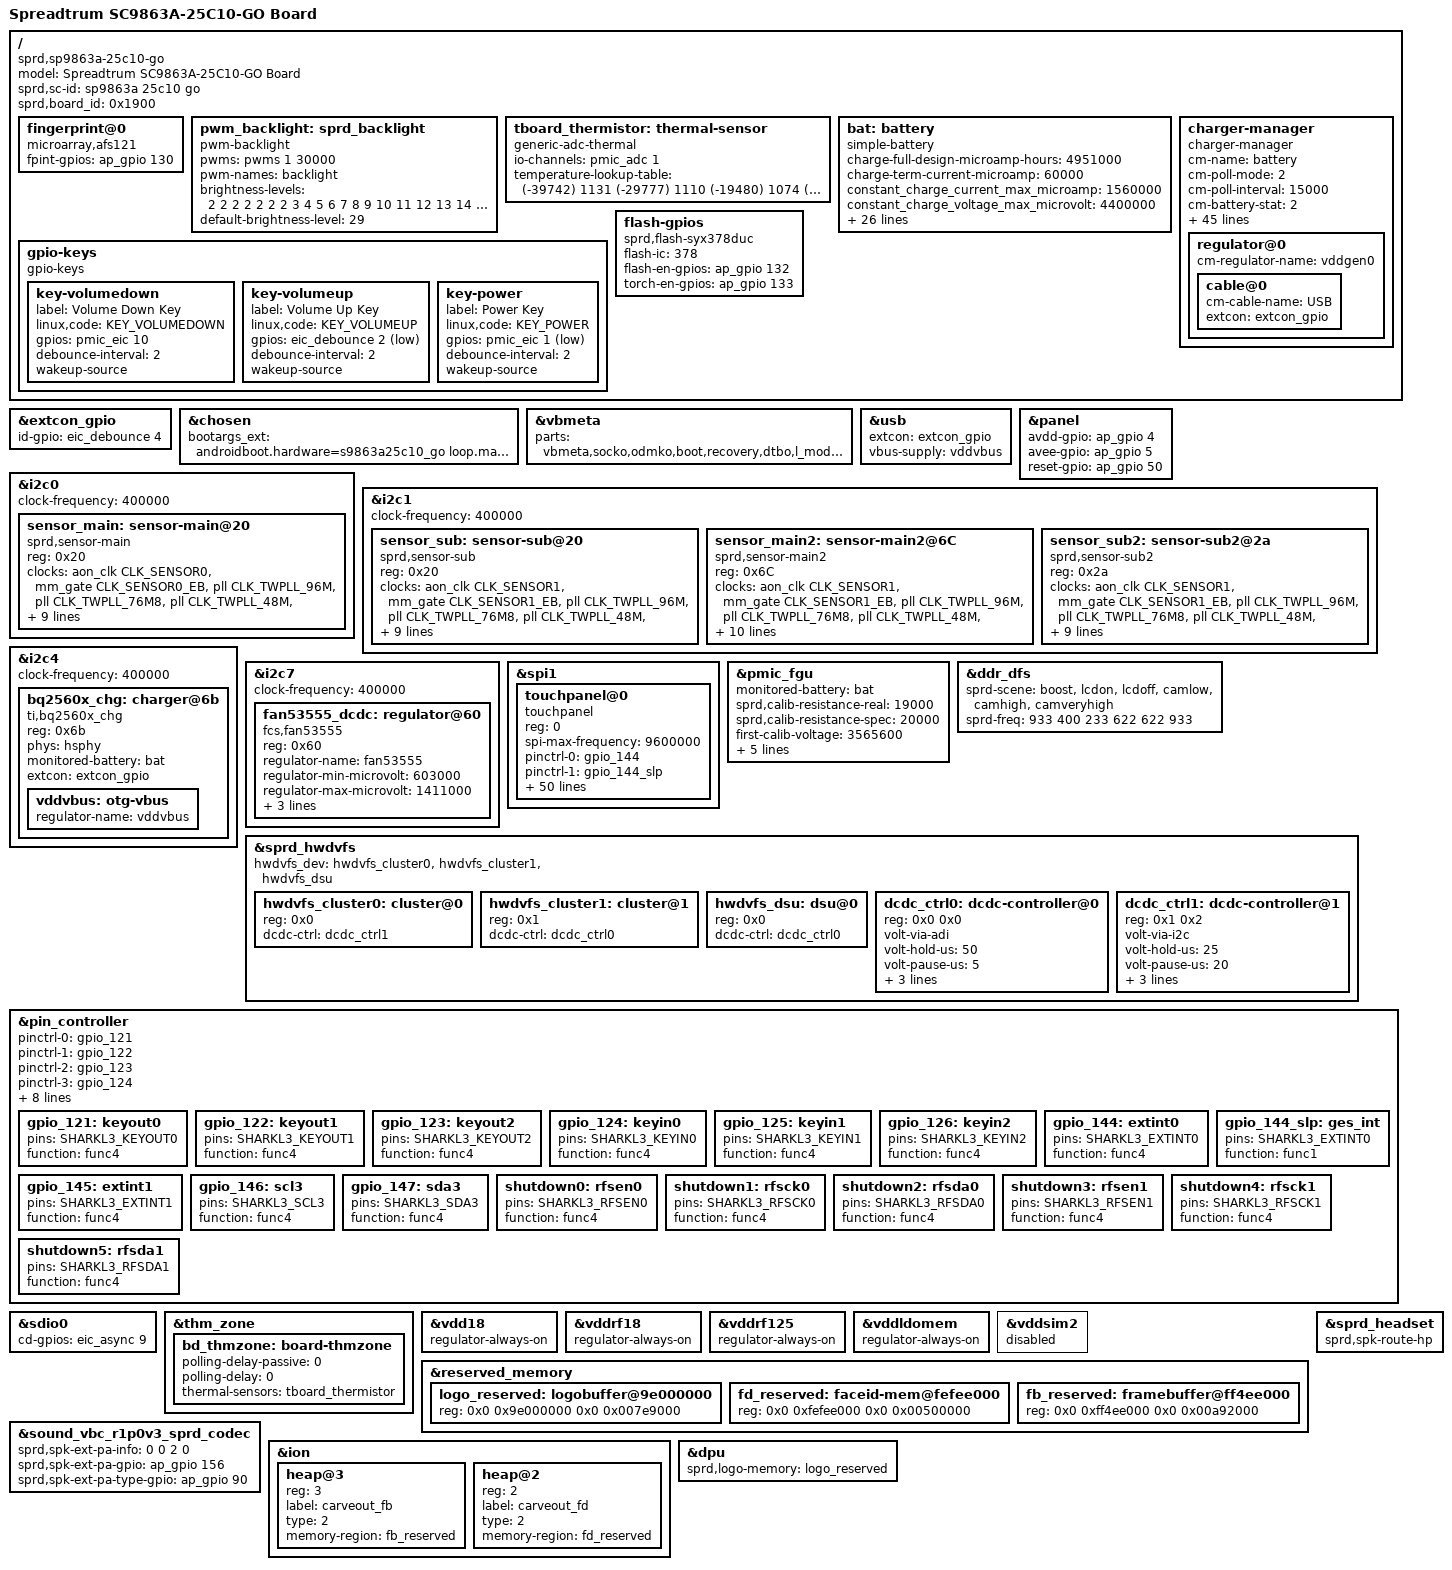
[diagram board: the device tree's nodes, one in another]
/dts-v1/;
/plugin/;

#include <dt-bindings/input/input.h>
#include <dt-bindings/gpio/gpio.h>
#include <dt-bindings/clock/sprd,sc9863a-clk.h>
#include "lcd/lcd_icnl9911c_truly_mipi_hdp.dtsi"
#include "lcd/lcd_nt35695_truly_mipi_fhd.dtsi"
#include "lcd/lcd_nt35532_truly_mipi_fhd.dtsi"
#include "lcd/lcd_nt35596_boe_mipi_fhd.dtsi"
#include "lcd/lcd_dummy_mipi.dtsi"

/ {
	model = "Spreadtrum SC9863A-25C10-GO Board";
	compatible = "sprd,sp9863a-25c10-go", "sprd,sc9863a";
	sprd,sc-id = "sp9863a 25c10 go";
	sprd,board_id = <0x1900>; //XX00:base board,XX00~XXFF:customize board

	fragment {
		target-path = "/";
		__overlay__ {
			fingerprint@0 {
				compatible = "microarray,afs121";
				fpint-gpios = <&ap_gpio 130 0>;
			};
			pwm_backlight: sprd_backlight {
				compatible = "pwm-backlight";
				pwms = <&pwms 1 30000>;
				pwm-names = "backlight";
				brightness-levels = <
								  2   2   2   2
					  2   2   2   3   4   5   6   7   8   9
					 10  11  12  13  14  15  16  17  18  19
					 20  21  22  23  24  25  26  27  28  29
					 30  31  32  33  34  35  36  37  38  39
					 40  41  42  43  44  45  46  47  48  49
					 50  51  52  53  54  55  56  57  58  59
					 60  61  62  63  64  65  66  67  68  69
					 70  71  72  73  74  75  76  77  78  79
					 80  81  82  83  84  85  86  87  88  89
					 90  91  92  93  94  95  96  97  98  99
					100 101 102 103 104 105 106 107 108 109
					110 111 112 113 114 115 116 117 118 119
					120 121 122 123 124 125 126 127 128 129
					130 131 132 133 134 135 136 137 138 139
					140 141 142 143 144 145 146 147 148 149
					150 151 152 153 154 155 156 157 158 159
					160 161 162 163 164 165 166 167 168 169
					170 171 172 173 174 175 176 177 178 179
					180 181 182 183 184 185 186 187 188 189
					190 191 192 193 194 195 196 197 198 199
					200 201 202 203 204 205 206 207 208 209
					210 211 212 213 214 215 216 217 218 219
					220 221 222 223 224 225 226 227 228 229
					230 231 232 233 234 235 236 237 238 239
					240 241 242 243 244 245 246 247 248 249
					250 251
				>;
				default-brightness-level = <29>;
			};

			tboard_thermistor:thermal-sensor {
				compatible = "generic-adc-thermal";
				#thermal-sensor-cells = <0>;
				io-channels = <&pmic_adc 1>;
				io-channel-names = "sensor-channel";
				temperature-lookup-table = <	(-39742) 1131
								(-29777) 1110
								(-19480) 1074
								(-4679) 983
								10110 838
								24805 654
								44922 413
								54903 316
								64895 238
								74884 178
								84883 133
								94883 100
								104880 75
								114889 57
								124872 43 >;
			};

			bat: battery {
				compatible = "simple-battery";
				charge-full-design-microamp-hours = <4951000>;
				charge-term-current-microamp = <60000>;
				constant_charge_current_max_microamp = <1560000>;
				constant_charge_voltage_max_microvolt = <4400000>;
				factory-internal-resistance-micro-ohms = <134000>;
				voltage-min-design-microvolt = <3455000>;
				ocv-capacity-celsius = <20>;
				ocv-capacity-table-0 = <4371000 100>, <4306000 95>, <4247000 90>,
							<4190000 85>, <4135000 80>, <4082000 75>,
							<4034000 70>, <3989000 65>, <3947000 60>,
							<3893000 55>, <3857000 50>, <3831000 45>,
							<3811000 40>, <3795000 35>, <3781000 30>,
							<3763000 25>, <3744000 20>, <3720000 15>,
							<3692000 10>, <3676000 5>,  <3400000 0>;
				voltage-temp-table = <1092000 800>, <984000 850>, <878000 900>,
							  <775000 950>, <679000 1000>, <591000 1050>,
							  <511000 1100>, <440000 1150>, <378000 1200>,
							  <324000 1250>, <278000 1300>, <238000 1350>,
							  <204000 1400>, <175000 1450>, <150000 1500>,
							  <129000 1550>, <111000 1600>, <96000 1650>,
							  <83000  1700>, <72000  1750>, <63000  1800>;
				capacity-temp-table = <50 100>, <25 100>, <10 100>, <0 96>, <(-10) 92>, <(-20) 78>;
				resistance-temp-table = <50 100>, <25 100>, <10 177>, <0 809>, <(-10) 903>, <(-20) 1002>;
				charge-sdp-current-microamp = <500000 500000>;
				charge-dcp-current-microamp = <1560000 1600000>;
				charge-cdp-current-microamp = <1300000 1300000>;
				charge-unknown-current-microamp = <500000 500000>;
			};

			charger-manager {
				status = "okay";
				compatible = "charger-manager";
				cm-name = "battery";
				cm-poll-mode = <2>;
				cm-poll-interval = <15000>;
				cm-battery-stat = <2>;

				cm-fullbatt-vchkdrop-ms = <30000>;
				cm-fullbatt-vchkdrop-volt = <100000>;
				cm-fullbatt-voltage = <4378000>;
				cm-fullbatt-current = <240000>;
				cm-first-fullbatt-current = <360000>;
				cm-fullbatt-capacity = <100>;

				cm-num-chargers = <1>;
				cm-chargers = "bq2560x_charger";
				cm-fuel-gauge = "sc27xx-fgu";

				/* in deci centigrade */
				cm-battery-cold = <200>;
				cm-battery-cold-in-minus;
				cm-battery-hot = <800>;
				cm-battery-temp-diff = <100>;

				/* Allow charging for 20hr */
				cm-charging-max = <72000000>;
				/* recovery charging after stop charging 45min */
				cm-discharging-max = <2700000>;

				/* the interval to feed charger watchdog */
				cm-wdt-interval = <60>;

				/* drop voltage in microVolts to allow shutdown */
				cm-shutdown-voltage = <3100000>;

				/* when 99% of the time is exceeded, it will be forced to 100% */
				cm-tickle-time-out = <1500>;

				/* how much time to allow capacity change */
				cm-one-cap-time = <30>;

				/* when the safe charging voltage is exceeded, stop charging */
				cm-charge-voltage-max = <6500000>;
				/* drop voltage in microVolts to restart charging */
				cm-charge-voltage-drop = <700000>;
				cm-dcp-jeita-temp-table = <1000 1020 0 4400000>, <1050 1060 500000 4400000>, <1120 1140 1400000 4400000>,
					<1450 1430 1560000 4400000>, <1550 1530 1560000 4200000>;
				cm-sdp-jeita-temp-table = <1000 1020 0 4400000>, <1050 1060 500000 4400000>, <1120 1140 500000 4400000>,
					<1450 1430 500000 4400000>, <1550 1530 500000 4200000>;
				cm-cdp-jeita-temp-table = <1000 1020 0 4400000>, <1050 1060 500000 4400000>, <1120 1140 1400000 4400000>,
					<1450 1430 1500000 4400000>, <1550 1530 1500000 4200000>;
				cm-unknown-jeita-temp-table = <1000 1020 0 4400000>, <1050 1060 500000 4400000>, <1120 1140 500000 4400000>,
					<1450 1430 500000 4400000>, <1550 1530 500000 4200000>;

				monitored-battery = <&bat>;

				cm-cap-remap-table = <1 2 3>, <2 3 2>, <98 99 2>, <99 100 3>;

				regulator@0 {
					cm-regulator-name = "vddgen0";
					cable@0 {
						cm-cable-name = "USB";
						extcon = <&extcon_gpio>;
					};
				};
			};

			gpio-keys {
				compatible = "gpio-keys";

				key-volumedown {
					label = "Volume Down Key";
					linux,code = <KEY_VOLUMEDOWN>;
					gpios = <&pmic_eic 10 GPIO_ACTIVE_HIGH>;
					debounce-interval = <2>;
					wakeup-source;
				};

				key-volumeup {
					label = "Volume Up Key";
					linux,code = <KEY_VOLUMEUP>;
					gpios = <&eic_debounce 2 GPIO_ACTIVE_LOW>;
					debounce-interval = <2>;
					wakeup-source;
				};

				key-power {
					label = "Power Key";
					linux,code = <KEY_POWER>;
					gpios = <&pmic_eic 1 GPIO_ACTIVE_LOW>;
					debounce-interval = <2>;
					wakeup-source;
				};
			};
			flash-gpios {
				compatible = "sprd,flash-syx378duc";
				flash-ic = <378>;
				flash-en-gpios = <&ap_gpio 132 0>;
				torch-en-gpios = <&ap_gpio 133 0>;
				status = "okay";
			};
		};
	};
};

&extcon_gpio {
	id-gpio = <&eic_debounce 4 GPIO_ACTIVE_HIGH>;
};

&chosen {
	bootargs_ext = "androidboot.hardware=s9863a25c10_go loop.max_part=7 androidboot.dtbo_idx=0";
};

&vbmeta {
	parts = "vbmeta,socko,odmko,boot,recovery,dtbo,l_modem,pm_sys,l_ldsp,l_gdsp";
};

&usb {
	extcon = <&extcon_gpio>;
	vbus-supply = <&vddvbus>;
};

&panel {
	avdd-gpio = <&ap_gpio 4 GPIO_ACTIVE_HIGH>;
	avee-gpio = <&ap_gpio 5 GPIO_ACTIVE_HIGH>;
	reset-gpio = <&ap_gpio 50 GPIO_ACTIVE_HIGH>;
};

&i2c0 {
	status = "okay";
	clock-frequency = <400000>;

	sensor_main: sensor-main@20 {
		compatible = "sprd,sensor-main";
		reg = <0x20>;
		clock-names = "clk_src","sensor_eb",
			"clk_96m","clk_76m8",
			"clk_48m","clk_26m";
		clocks = <&aon_clk CLK_SENSOR0>, <&mm_gate CLK_SENSOR0_EB>,
			<&pll CLK_TWPLL_96M>,<&pll CLK_TWPLL_76M8>,
			<&pll CLK_TWPLL_48M>,<&ext_26m>;
		vddio-supply = <&vddcamio>;
		vddcama-supply = <&vddcama>;
		vddcamd-supply = <&vddcamd>;
		vddcammot-supply = <&vddcammot>;
		sprd,phyid = <1>;
		csi = <&csi0>;
		reset-gpios = <&ap_gpio 44 0>;
		power-down-gpios = <&ap_gpio 46 0>;
	};
};

&i2c1 {
	status = "okay";
	clock-frequency = <400000>;

	sensor_sub: sensor-sub@20 {
		compatible = "sprd,sensor-sub";
		reg = <0x20>;
		clock-names = "clk_src","sensor_eb",
			"clk_96m","clk_76m8",
			"clk_48m","clk_26m";
		clocks = <&aon_clk CLK_SENSOR1>, <&mm_gate CLK_SENSOR1_EB>,
			<&pll CLK_TWPLL_96M>,<&pll CLK_TWPLL_76M8>,
			<&pll CLK_TWPLL_48M>,<&ext_26m>;
		vddio-supply = <&vddcamio>;
		vddcama-supply = <&vddcama>;
		vddcamd-supply = <&vddcamd>;
		vddcammot-supply = <&vddcammot>;
		sprd,phyid = <3>;
		csi = <&csi0>;
		reset-gpios = <&ap_gpio 41 0>;
		power-down-gpios = <&ap_gpio 40 0>;
	};

	sensor_main2: sensor-main2@6C {
		compatible = "sprd,sensor-main2";
		reg = <0x6C>;
		clock-names = "clk_src","sensor_eb",
			"clk_96m","clk_76m8",
			"clk_48m","clk_26m";
		clocks = <&aon_clk CLK_SENSOR1>, <&mm_gate CLK_SENSOR1_EB>,
			<&pll CLK_TWPLL_96M>,<&pll CLK_TWPLL_76M8>,
			<&pll CLK_TWPLL_48M>,<&ext_26m>;
		vddio-supply = <&vddcamio>;
		vddcama-supply = <&vddcama>;
		vddcamd-supply = <&vddcamd>;
		vddcammot-supply = <&vddcammot>;
		sprd,phyid = <3>;
		csi = <&csi1>;
		/*avdd-gpios=<&ap_gpio 140 0>;*/
		dvdd-gpios=<&ap_gpio 62 0>;
		reset-gpios = <&ap_gpio 45 0>;
		power-down-gpios = <&ap_gpio 47 0>;
	};

	sensor_sub2: sensor-sub2@2a {
		compatible = "sprd,sensor-sub2";
		reg = <0x2a>;
		clock-names = "clk_src","sensor_eb",
			"clk_96m","clk_76m8",
			"clk_48m","clk_26m";
		clocks = <&aon_clk CLK_SENSOR1>, <&mm_gate CLK_SENSOR1_EB>,
			<&pll CLK_TWPLL_96M>,<&pll CLK_TWPLL_76M8>,
			<&pll CLK_TWPLL_48M>,<&ext_26m>;
		vddio-supply = <&vddcamio>;
		vddcama-supply = <&vddcama>;
		vddcamd-supply = <&vddcamd>;
		vddcammot-supply = <&vddcammot>;
		sprd,phyid = <4>;
		csi = <&csi2>;
		/*avdd-gpios=<&ap_gpio 140 0>;*/
		reset-gpios = <&ap_gpio 45 0>;
		power-down-gpios = <&ap_gpio 40 0>;
	};
};

&i2c4 {
	status = "okay";
	clock-frequency = <400000>;

	bq2560x_chg: charger@6b {
		compatible = "ti,bq2560x_chg";
		reg = <0x6b>;
		phys = <&hsphy>;
		monitored-battery = <&bat>;
		extcon = <&extcon_gpio>;
		vddvbus:otg-vbus {
			regulator-name = "vddvbus";
		};
	};

	/*
	flash_ic: flash-ic@63 {
		compatible = "sprd,flash-ocp8137";
		reg = <0x63>;
		sprd,flash-ic = <8137>;
		sprd,torch = <1>;
		sprd,preflash = <1>;
		sprd,highlight = <1>;
		sprd,torch-level = <128>;
		sprd,preflash-level = <128>;
		sprd,highlight-level = <128>;
		sprd,lvfm-enable = <1>;
		flash-torch-en-gpios = <&ap_gpio 88 0>;
		flash-chip-en-gpios = <&ap_gpio 89 0>;
		flash-en-gpios = <&ap_gpio 76 0>;
		flash-sync-gpios = <&ap_gpio 141 0>;
	};*/
};

&i2c7 {
	status = "okay";
	clock-frequency = <400000>;

	fan53555_dcdc: regulator@60 {
		compatible = "fcs,fan53555";
		reg = <0x60>;
		regulator-name = "fan53555";
		regulator-min-microvolt = <603000>;
		regulator-max-microvolt = <1411000>;
		regulator-ramp-delay = <64000>;
		regulator-always-on;
		fcs,suspend-voltage-selector = <1>;
	};
};

&spi1 {
	status = "okay";

	touchpanel@0 {
		//ts common parameter
		compatible = "touchpanel";
		reg = <0>; //Same as CS ID
		status = "ok";

		spi-max-frequency = <9600000>;	//4800000,9600000,15000000,19200000

		pinctrl-names = "gpio_144", "gpio_144_slp";
		pinctrl-0 = <&gpio_144>;
		pinctrl-1 = <&gpio_144_slp>;
		ts,rst-gpio = <&ap_gpio 145 GPIO_ACTIVE_HIGH>;
		ts,irq-gpio = <&ap_gpio 144 0x00>;
		ges,irq-gpio = <&eic_debounce 0 GPIO_ACTIVE_HIGH>;

        /*GC7202*/
		gts,test-chip-id;
		gts,chip-id = [72 02];

		gts,test-open;
		gts,open-cb = <200>;
		gts,open-min = <500>;


		gts,test-short;
		gts,short-cb = <10>;
		gts,short-min = <200>;

		/*icnl9911c ===========start===========*/
		touch,max-touch-number = <5>;
		touch,display-coords =  <0 0 720 1600>;
		cts,x-res = <720>;
		cts,y-res = <1600>;

 		/* selftest settings */
		cts,test-reset-pin;
		//cts,test-int-pin;

		cts,test-rawdata;
		cts,test-rawdata-frames = <1>;
		cts,rawdata-min = <1400>;//base 1100
		cts,rawdata-max = <2600>;

		cts,test-noise;
		cts,test-noise-frames = <16>;
		cts,noise-max = <80>;

		cts,test-open;
		cts,open-min = <2772>;

		cts,test-short;
		cts,short-min = <500>;

		//cts,test-compensate-cap;
		cts,compensate-cap-min = <1>;
		cts,compensate-cap-max = <126>;

		/* Charger detect */
		cts,touch-charger-detect-enable;
		cts,touch-charger-detect-type = "notify"; /* notify, poll */
		cts,touch-charger-detect-psy-name = "battery";
		cts,touch-charger-detect-psp = "POWER_SUPPLY_PROP_ONLINE";
		cts,touch-charger-detect-psp-poll-interval = <1000>;

		/* Earjack detect */
		cts,touch-earjack-detect-enable;
		/* MTK:  /sys/bus/platform/drivers/Accdet_Driver/state,
		Sprd: /sys/kernel/headset/state
		QCOM: None, and disable it */
		cts,touch-earjack-state-filepath = "/sys/kernel/headset/state";
		cts,touch-earjack-poll-interval = <1000>;
		/*icnl9911c ===========end===========*/

		/*nt36525B*/
		/* 672A, 525B, 675, 526, 672C */
		nvt,swrst-n8-addr = <0x03F0FE>;
		nvt,spi-rd-fast-addr = <0x03F310>;
		/* Charger detect */
		nvt,touch-charger-detect-enable;
		nvt,touch-charger-detect-type = "notify"; /* notify, poll */
		nvt,touch-charger-detect-psy-name = "battery";
		nvt,touch-charger-detect-psp = "POWER_SUPPLY_PROP_ONLINE";
		nvt,touch-charger-detect-psp-poll-interval = <1000>;
		/* MP */
		nvt,mp-support-dt;

		#include "sp9863a-25c10_go-overlay-nvt_mp_pid7234.dtsi"
	};
};

&pmic_fgu {
	monitored-battery = <&bat>;
	sprd,calib-resistance-real = <19000>;
	sprd,calib-resistance-spec = <20000>;
	first-calib-voltage = <3565600>;
	first-calib-capacity = <50>;
	fgu-capacity-track;
	fullbatt-track-end-vol = <4295>;
	fullbatt-track-end-cur = <130>;
	phys = <&hsphy>;
};

&panel {
	avdd-gpio = <&ap_gpio 4 GPIO_ACTIVE_HIGH>;
	avee-gpio = <&ap_gpio 5 GPIO_ACTIVE_HIGH>;
	reset-gpio = <&ap_gpio 50 GPIO_ACTIVE_HIGH>;
};

&ddr_dfs {
	sprd-scene = "boost", "lcdon", "lcdoff", "camlow",
			"camhigh", "camveryhigh";
	sprd-freq = <933 400 233 622 622 933>;
};

&sprd_hwdvfs {
	hwdvfs_dev = <&hwdvfs_cluster0>,
		<&hwdvfs_cluster1>,
		<&hwdvfs_dsu>;

	hwdvfs_cluster0: cluster@0 {
		reg = <0x0>;
		dcdc-ctrl = <&dcdc_ctrl1>;
	};

	hwdvfs_cluster1: cluster@1 {
		reg = <0x1>;
		dcdc-ctrl = <&dcdc_ctrl0>;
	};

	hwdvfs_dsu: dsu@0 {
		reg = <0x0>;
		dcdc-ctrl = <&dcdc_ctrl0>;
	};

	dcdc_ctrl0: dcdc-controller@0 {
		reg = <0x0 0x0>;
		volt-via-adi;
		volt-hold-us = <50>;
		volt-pause-us = <5>;
		volt-timeout-us = <800>;
		volt-stable-us  = <5>;
		volt-max-step-microvolt = <25000>;
	};

	dcdc_ctrl1: dcdc-controller@1 {
		reg = <0x1 0x2>;
		volt-via-i2c;
		volt-hold-us = <25>;
		volt-pause-us = <20>;
		volt-timeout-us = <800>;
		volt-stable-us  = <25>;
		volt-max-step-microvolt = <1200004>;
	};
};

&pin_controller {
	pinctrl-names =
	/* keyout0 ~ keyout2 */
	"gpio_121", "gpio_122", "gpio_123",
	/* keyin0 ~ keyin2 */
	"gpio_124", "gpio_125", "gpio_126",
	/* extint0, extint1, scl3, sda3 */
	"gpio_144", "gpio_145", "gpio_146", "gpio_147",
	/* Note:If create a new board,need to add the shutdown node */
	"shutdown";
	pinctrl-0 = <&gpio_121>;
	pinctrl-1 = <&gpio_122>;
	pinctrl-2 = <&gpio_123>;
	pinctrl-3 = <&gpio_124>;
	pinctrl-4 = <&gpio_125>;
	pinctrl-5 = <&gpio_126>;
	pinctrl-6 = <&gpio_144>;
	pinctrl-7 = <&gpio_145>;
	pinctrl-8 = <&gpio_146>;
	pinctrl-9 = <&gpio_147>;
	pinctrl-10 = <&shutdown0
			&shutdown1
			&shutdown2
			&shutdown3
			&shutdown4
			&shutdown5>;

	gpio_121: keyout0 {
		pins = "SHARKL3_KEYOUT0";
		function = "func4";
	};

	gpio_122: keyout1 {
		pins = "SHARKL3_KEYOUT1";
		function = "func4";
	};

	gpio_123: keyout2 {
		pins = "SHARKL3_KEYOUT2";
		function = "func4";
	};

	gpio_124: keyin0 {
		pins = "SHARKL3_KEYIN0";
		function = "func4";
	};

	gpio_125: keyin1 {
		pins = "SHARKL3_KEYIN1";
		function = "func4";
	};

	gpio_126: keyin2 {
		pins = "SHARKL3_KEYIN2";
		function = "func4";
	};

	gpio_144: extint0 {
		pins = "SHARKL3_EXTINT0";
		function = "func4";
	};
	
	gpio_144_slp: ges_int {
        pins = "SHARKL3_EXTINT0";
        function = "func1";
    };

	gpio_145: extint1 {
		pins = "SHARKL3_EXTINT1";
		function = "func4";
	};

	gpio_146: scl3 {
		pins = "SHARKL3_SCL3";
		function = "func4";
	};

	gpio_147: sda3 {
		pins = "SHARKL3_SDA3";
		function = "func4";
	};

	shutdown0: rfsen0 {
		pins = "SHARKL3_RFSEN0";
		function = "func4";
	};

	shutdown1: rfsck0 {
		pins = "SHARKL3_RFSCK0";
		function = "func4";
	};

	shutdown2: rfsda0 {
		pins = "SHARKL3_RFSDA0";
		function = "func4";
	};

	shutdown3: rfsen1 {
		pins = "SHARKL3_RFSEN1";
		function = "func4";
	};

	shutdown4: rfsck1 {
		pins = "SHARKL3_RFSCK1";
		function = "func4";
	};

	shutdown5: rfsda1 {
		pins = "SHARKL3_RFSDA1";
		function = "func4";
	};
};

&sdio0 {
	cd-gpios = <&eic_async 9 GPIO_ACTIVE_HIGH>;
};

&thm_zone {
	bd_thmzone: board-thmzone {
		polling-delay-passive = <0>;
		polling-delay = <0>;
		thermal-sensors = <&tboard_thermistor>;
	};
};

&vdd18 {
	regulator-always-on;
};

&vddrf18 {
	regulator-always-on;
};

&vddrf125 {
	regulator-always-on;
};

&vddldomem {
	regulator-always-on;
};

&vddsim2 {
	status = "disabled";
};

&reserved_memory {
	logo_reserved: logobuffer@9e000000{
		reg = <0x0 0x9e000000 0x0 0x007e9000>;
	};

	fd_reserved: faceid-mem@fefee000 {
		reg = <0x0 0xfefee000 0x0 0x00500000>;
	};

	fb_reserved: framebuffer@ff4ee000 {
		reg = <0x0 0xff4ee000 0x0 0x00a92000>;
	};
};

&sprd_headset {
	status = "okay";
	sprd,spk-route-hp;
};

&sound_vbc_r1p0v3_sprd_codec {
	status = "okay";
	sprd,spk-ext-pa-info = <0 0 2 0>;
	sprd,spk-ext-pa-gpio = <&ap_gpio 156 0>;
	sprd,spk-ext-pa-type-gpio = <&ap_gpio 90 0>;
};

&ion {
	heap@3 {
		reg = <3>;
		label = "carveout_fb";
		type = <2>;
		memory-region = <&fb_reserved>;
	};

	heap@2 {
		reg = <2>;
		label = "carveout_fd";
		type = <2>;
		memory-region = <&fd_reserved>;
	};
};

&dpu {
	sprd,logo-memory = <&logo_reserved>;
};
